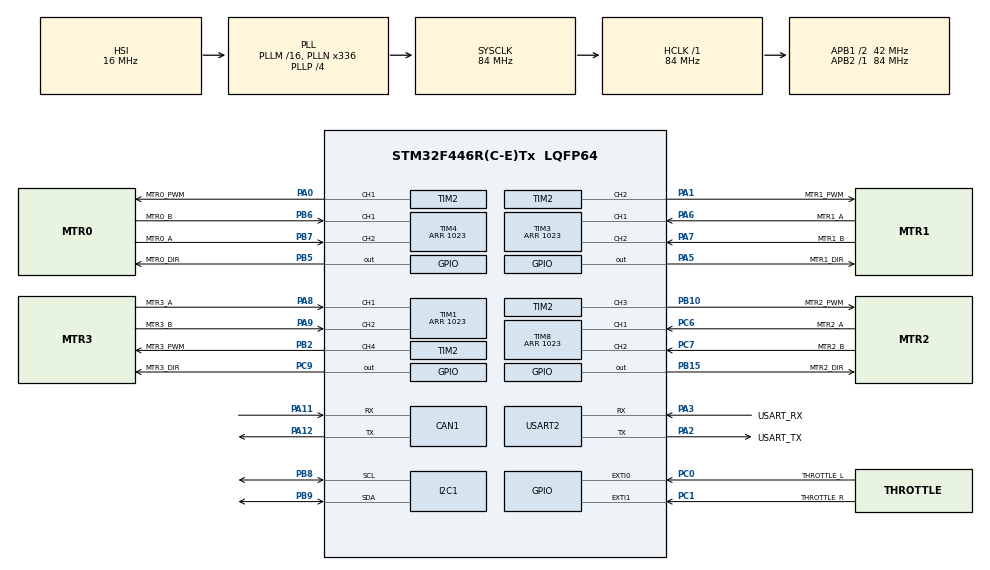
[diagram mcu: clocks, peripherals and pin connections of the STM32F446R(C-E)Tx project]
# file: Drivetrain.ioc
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CAN1.CalculateTimeQuantum=380.95238095238096
I2C1.OwnAddress=1
Mcu.Family=STM32F4
Mcu.Name=STM32F446R(C-E)Tx
Mcu.Package=LQFP64
NVIC.CAN1_RX0_IRQn=true\:0\:0\:false\:false\:true\:true
NVIC.CAN1_RX1_IRQn=true\:0\:0\:false\:false\:true\:true
NVIC.CAN1_SCE_IRQn=true\:0\:0\:false\:false\:true\:true
NVIC.CAN1_TX_IRQn=true\:0\:0\:false\:false\:true\:true
NVIC.I2C1_ER_IRQn=true\:0\:0\:false\:false\:true\:true
NVIC.I2C1_EV_IRQn=true\:0\:0\:false\:false\:true\:true
NVIC.PriorityGroup=NVIC_PRIORITYGROUP_0
NVIC.TIM1_UP_TIM10_IRQn=true\:0\:0\:false\:false\:true\:false
NVIC.TIM8_TRG_COM_TIM14_IRQn=true\:0\:0\:false\:false\:true\:true
NVIC.TIM8_UP_TIM13_IRQn=true\:0\:0\:false\:false\:true\:true
NVIC.TimeBase=TIM1_UP_TIM10_IRQn
NVIC.TimeBaseIP=TIM10
PA0-WKUP.GPIO_Label=MTR0_PWM
PA0-WKUP.Signal=S_TIM2_CH1_ETR
PA1.GPIO_Label=MTR1_PWM
PA1.Signal=S_TIM2_CH2
PA11.Mode=Master
PA11.Signal=CAN1_RX
PA12.Mode=Master
PA12.Signal=CAN1_TX
PA13.GPIO_Label=TMS
PA13.Mode=Serial_Wire
PA13.Signal=SYS_JTMS-SWDIO
PA14.GPIO_Label=TCK
PA14.Mode=Serial_Wire
PA14.Signal=SYS_JTCK-SWCLK
PA2.GPIO_Label=USART_TX
PA2.Mode=Asynchronous
PA2.Signal=USART2_TX
PA3.GPIO_Label=USART_RX
PA3.Mode=Asynchronous
PA3.Signal=USART2_RX
PA5.GPIO_Label=MTR1_DIR
PA5.Signal=GPIO_Output
PA6.GPIO_Label=MTR1_A
PA6.Signal=S_TIM3_CH1
PA7.GPIO_Label=MTR1_B
PA7.Signal=S_TIM3_CH2
PA8.GPIO_Label=MTR3_A
PA8.Signal=S_TIM1_CH1
PA9.GPIO_Label=MTR3_B
PA9.Signal=S_TIM1_CH2
PB10.GPIO_Label=MTR2_PWM
PB10.Signal=S_TIM2_CH3
PB15.GPIO_Label=MTR2_DIR
PB15.Signal=GPIO_Output
PB2.GPIO_Label=MTR3_PWM
PB2.Signal=S_TIM2_CH4
PB3.GPIO_Label=SWO
PB3.Signal=SYS_JTDO-SWO
PB5.GPIO_Label=MTR0_DIR
PB5.Signal=GPIO_Output
PB6.GPIO_Label=MTR0_B
PB6.Signal=S_TIM4_CH1
PB7.GPIO_Label=MTR0_A
PB7.Signal=S_TIM4_CH2
PB8.Mode=I2C
PB8.Signal=I2C1_SCL
PB9.Mode=I2C
PB9.Signal=I2C1_SDA
PC0.GPIO_Label=THROTTLE_L
PC0.GPIO_ModeDefaultEXTI=GPIO_MODE_IT_RISING_FALLING
PC0.Signal=GPXTI0
PC1.GPIO_Label=THROTTLE_R
PC1.Signal=GPXTI1
PC6.GPIO_Label=MTR2_A
PC6.Signal=S_TIM8_CH1
PC7.GPIO_Label=MTR2_B
PC7.Signal=S_TIM8_CH2
PC9.GPIO_Label=MTR3_DIR
PC9.Signal=GPIO_Output
PH0-OSC_IN.Mode=HSE-External-Oscillator
PH0-OSC_IN.Signal=RCC_OSC_IN
PH1-OSC_OUT.Mode=HSE-External-Oscillator
PH1-OSC_OUT.Signal=RCC_OSC_OUT
ProjectManager.HeapSize=0x200
ProjectManager.StackSize=0x400
ProjectManager.TargetToolchain=EWARM V8
RCC.48MHZClocksFreq_Value=84000000
RCC.AHBFreq_Value=84000000
RCC.APB1CLKDivider=RCC_HCLK_DIV2
RCC.APB1Freq_Value=42000000
RCC.APB1TimFreq_Value=84000000
RCC.APB2Freq_Value=84000000
RCC.APB2TimFreq_Value=84000000
RCC.CortexFreq_Value=84000000
RCC.FLatency-AdvancedSettings=FLASH_LATENCY_2
RCC.HCLKFreq_Value=84000000
RCC.HSE_VALUE=8000000
RCC.HSI_VALUE=16000000
RCC.PLLN=336
RCC.PLLP=RCC_PLLP_DIV4
RCC.SYSCLKFreq_VALUE=84000000
RCC.SYSCLKSource=RCC_SYSCLKSOURCE_PLLCLK
RCC.USBFreq_Value=168000000
RCC.VCOOutputFreq_Value=336000000
SH.S_TIM1_CH1.0=TIM1_CH1,Encoder_Interface
SH.S_TIM1_CH2.0=TIM1_CH2,Encoder_Interface
SH.S_TIM2_CH1_ETR.0=TIM2_CH1,PWM Generation1 CH1
SH.S_TIM2_CH2.0=TIM2_CH2,PWM Generation2 CH2
SH.S_TIM2_CH3.0=TIM2_CH3,PWM Generation3 CH3
SH.S_TIM2_CH4.0=TIM2_CH4,PWM Generation4 CH4
SH.S_TIM3_CH1.0=TIM3_CH1,Encoder_Interface
SH.S_TIM3_CH2.0=TIM3_CH2,Encoder_Interface
SH.S_TIM4_CH1.0=TIM4_CH1,Encoder_Interface
SH.S_TIM4_CH2.0=TIM4_CH2,Encoder_Interface
SH.S_TIM8_CH1.0=TIM8_CH1,Encoder_Interface
SH.S_TIM8_CH2.0=TIM8_CH2,Encoder_Interface
TIM1.EncoderMode=TIM_ENCODERMODE_TI1
TIM1.Period=1023
TIM2.Channel-PWM\ Generation1\ CH1=TIM_CHANNEL_1
TIM2.Channel-PWM\ Generation2\ CH2=TIM_CHANNEL_2
TIM2.Channel-PWM\ Generation3\ CH3=TIM_CHANNEL_3
TIM2.Channel-PWM\ Generation4\ CH4=TIM_CHANNEL_4
TIM2.Period=8399
TIM3.EncoderMode=TIM_ENCODERMODE_TI1
TIM3.Period=1023
TIM4.EncoderMode=TIM_ENCODERMODE_TI1
TIM4.Period=1023
TIM6.Period=65535
TIM6.Prescaler=83
TIM8.EncoderMode=TIM_ENCODERMODE_TI1
TIM8.Period=1023
USART2.VirtualMode=VM_ASYNC
VP_CRC_VS_CRC.Mode=CRC_Activate
VP_SYS_VS_tim10.Mode=TIM10
VP_TIM6_VS_ClockSourceINT.Mode=Enable_Timer
board=NUCLEO-F446RE

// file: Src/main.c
/**
  ******************************************************************************
  * @file           : main.c
  * @brief          : Main program body
  ******************************************************************************
  ** This notice applies to any and all portions of this file
  * that are not between comment pairs USER CODE BEGIN and
  * USER CODE END. Other portions of this file, whether
  * inserted by the user or by software development tools
  * are owned by their respective copyright owners.
  *
  * COPYRIGHT(c) 2019 STMicroelectronics
  *
  * Redistribution and use in source and binary forms, with or without modification,
  * are permitted provided that the following conditions are met:
  *   1. Redistributions of source code must retain the above copyright notice,
  *      this list of conditions and the following disclaimer.
  *   2. Redistributions in binary form must reproduce the above copyright notice,
  *      this list of conditions and the following disclaimer in the documentation
  *      and/or other materials provided with the distribution.
  *   3. Neither the name of STMicroelectronics nor the names of its contributors
  *      may be used to endorse or promote products derived from this software
  *      without specific prior written permission.
  *
  * THIS SOFTWARE IS PROVIDED BY THE COPYRIGHT HOLDERS AND CONTRIBUTORS "AS IS"
  * AND ANY EXPRESS OR IMPLIED WARRANTIES, INCLUDING, BUT NOT LIMITED TO, THE
  * IMPLIED WARRANTIES OF MERCHANTABILITY AND FITNESS FOR A PARTICULAR PURPOSE ARE
  * DISCLAIMED. IN NO EVENT SHALL THE COPYRIGHT HOLDER OR CONTRIBUTORS BE LIABLE
  * FOR ANY DIRECT, INDIRECT, INCIDENTAL, SPECIAL, EXEMPLARY, OR CONSEQUENTIAL
  * DAMAGES (INCLUDING, BUT NOT LIMITED TO, PROCUREMENT OF SUBSTITUTE GOODS OR
  * SERVICES; LOSS OF USE, DATA, OR PROFITS; OR BUSINESS INTERRUPTION) HOWEVER
  * CAUSED AND ON ANY THEORY OF LIABILITY, WHETHER IN CONTRACT, STRICT LIABILITY,
  * OR TORT (INCLUDING NEGLIGENCE OR OTHERWISE) ARISING IN ANY WAY OUT OF THE USE
  * OF THIS SOFTWARE, EVEN IF ADVISED OF THE POSSIBILITY OF SUCH DAMAGE.
  *
  ******************************************************************************
  */
#include "main.h"
#include "stm32f4xx_hal.h"
#include "can.h"
#include "crc.h"
#include "i2c.h"
#include "tim.h"
#include "usart.h"
#include "gpio.h"

/* USER CODE BEGIN Includes */
#include "application.h"
/* USER CODE END Includes */

/* USER CODE BEGIN PV */
/* Private variables ---------------------------------------------------------*/

/* USER CODE END PV */

void SystemClock_Config(void);

/* USER CODE BEGIN PFP */
/* Private function prototypes -----------------------------------------------*/

/* USER CODE END PFP */

int main(void)
{

  /* MCU Configuration----------------------------------------------------------*/

  /* Reset of all peripherals, Initializes the Flash interface and the Systick. */
  HAL_Init();

  /* Configure the system clock */
  SystemClock_Config();

  /* Initialize all configured peripherals */
  MX_GPIO_Init();
  MX_TIM1_Init();
  MX_TIM3_Init();
  MX_TIM4_Init();
  MX_TIM8_Init();
  MX_USART2_UART_Init();
  MX_CAN1_Init();
  MX_TIM2_Init();
  MX_TIM6_Init();
  MX_I2C1_Init();
  MX_CRC_Init();
  /* USER CODE BEGIN 2 */
  /* Run our own main loop to escape the initialization code */
  app_run();
  /* USER CODE END 2 */

  /* Infinite loop */
  while (1)
  {

  }

}

void SystemClock_Config(void)
{

  RCC_OscInitTypeDef RCC_OscInitStruct;
  RCC_ClkInitTypeDef RCC_ClkInitStruct;

    /**Configure the main internal regulator output voltage
    */
  __HAL_RCC_PWR_CLK_ENABLE();

  __HAL_PWR_VOLTAGESCALING_CONFIG(PWR_REGULATOR_VOLTAGE_SCALE3);

    /**Initializes the CPU, AHB and APB busses clocks
    */
  RCC_OscInitStruct.OscillatorType = RCC_OSCILLATORTYPE_HSI;
  RCC_OscInitStruct.HSIState = RCC_HSI_ON;
  RCC_OscInitStruct.HSICalibrationValue = 16;
  RCC_OscInitStruct.PLL.PLLState = RCC_PLL_ON;
  RCC_OscInitStruct.PLL.PLLSource = RCC_PLLSOURCE_HSI;
  RCC_OscInitStruct.PLL.PLLM = 16;
  RCC_OscInitStruct.PLL.PLLN = 336;
  RCC_OscInitStruct.PLL.PLLP = RCC_PLLP_DIV4;
  RCC_OscInitStruct.PLL.PLLQ = 2;
  RCC_OscInitStruct.PLL.PLLR = 2;
  if (HAL_RCC_OscConfig(&RCC_OscInitStruct) != HAL_OK)
  {
    _Error_Handler(__FILE__, __LINE__);
  }

    /**Initializes the CPU, AHB and APB busses clocks
    */
  RCC_ClkInitStruct.ClockType = RCC_CLOCKTYPE_HCLK|RCC_CLOCKTYPE_SYSCLK
                              |RCC_CLOCKTYPE_PCLK1|RCC_CLOCKTYPE_PCLK2;
  RCC_ClkInitStruct.SYSCLKSource = RCC_SYSCLKSOURCE_PLLCLK;
  RCC_ClkInitStruct.AHBCLKDivider = RCC_SYSCLK_DIV1;
  RCC_ClkInitStruct.APB1CLKDivider = RCC_HCLK_DIV2;
  RCC_ClkInitStruct.APB2CLKDivider = RCC_HCLK_DIV1;

  if (HAL_RCC_ClockConfig(&RCC_ClkInitStruct, FLASH_LATENCY_2) != HAL_OK)
  {
    _Error_Handler(__FILE__, __LINE__);
  }

    /**Configure the Systick interrupt time
    */
  HAL_SYSTICK_Config(HAL_RCC_GetHCLKFreq()/1000);

    /**Configure the Systick
    */
  HAL_SYSTICK_CLKSourceConfig(SYSTICK_CLKSOURCE_HCLK);

  /* SysTick_IRQn interrupt configuration */
  HAL_NVIC_SetPriority(SysTick_IRQn, 0, 0);
}

void HAL_TIM_PeriodElapsedCallback(TIM_HandleTypeDef *htim)
{
  if (htim->Instance == TIM10) {
    HAL_IncTick();
  }
}

void _Error_Handler(char *file, int line)
{
  while(1)
  {
  }
}

/************************ (C) COPYRIGHT STMicroelectronics *****END OF FILE****/
